VERSION "1.2"

NS_ :

BS_:
BU_: AMK_Inverter

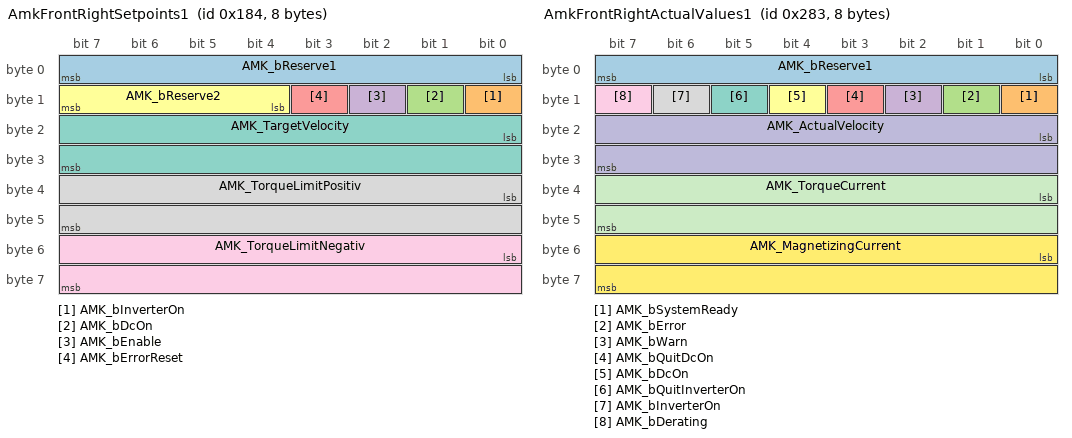
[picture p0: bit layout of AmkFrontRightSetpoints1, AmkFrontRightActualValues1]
BO_ 388 AmkFrontRightSetpoints1: 8 AMK_Inverter
 SG_ AMK_bReserve1           : 0|8@1+ (1,0) [0|255] "" Vector__XXX
 SG_ AMK_bInverterOn         : 8|1@1+ (1,0) [0|1]   "" Vector__XXX
 SG_ AMK_bDcOn               : 9|1@1+ (1,0) [0|1]   "" Vector__XXX
 SG_ AMK_bEnable             : 10|1@1+ (1,0) [0|1]  "" Vector__XXX
 SG_ AMK_bErrorReset         : 11|1@1+ (1,0) [0|1]  "" Vector__XXX
 SG_ AMK_bReserve2           : 12|4@1+ (1,0) [0|15]  "" Vector__XXX
 SG_ AMK_TargetVelocity      : 16|16@1- (1,0) [-32768|32767] "" Vector__XXX
 SG_ AMK_TorqueLimitPositiv  : 32|16@1- (1,0) [-32768|32767] "" Vector__XXX
 SG_ AMK_TorqueLimitNegativ  : 48|16@1- (1,0) [-32768|32767] "" Vector__XXX

BO_ 643 AmkFrontRightActualValues1: 8 AMK_Inverter
 SG_ AMK_bReserve1           : 0|8@1+ (1,0) [0|255] "" Vector__XXX
 SG_ AMK_bSystemReady        : 8|1@1+ (1,0) [0|1]   "" Vector__XXX
 SG_ AMK_bError              : 9|1@1+ (1,0) [0|1]   "" Vector__XXX
 SG_ AMK_bWarn               : 10|1@1+ (1,0) [0|1]  "" Vector__XXX
 SG_ AMK_bQuitDcOn           : 11|1@1+ (1,0) [0|1]  "" Vector__XXX
 SG_ AMK_bDcOn               : 12|1@1+ (1,0) [0|1]  "" Vector__XXX
 SG_ AMK_bQuitInverterOn     : 13|1@1+ (1,0) [0|1]  "" Vector__XXX
 SG_ AMK_bInverterOn         : 14|1@1+ (1,0) [0|1]  "" Vector__XXX
 SG_ AMK_bDerating           : 15|1@1+ (1,0) [0|1]  "" Vector__XXX
 SG_ AMK_ActualVelocity      : 16|16@1- (1,0) [-32768|32767] "" Vector__XXX
 SG_ AMK_TorqueCurrent       : 32|16@1- (1,0) [-32768|32767] "" Vector__XXX
 SG_ AMK_MagnetizingCurrent  : 48|16@1- (1,0) [-32768|32767] "" Vector__XXX

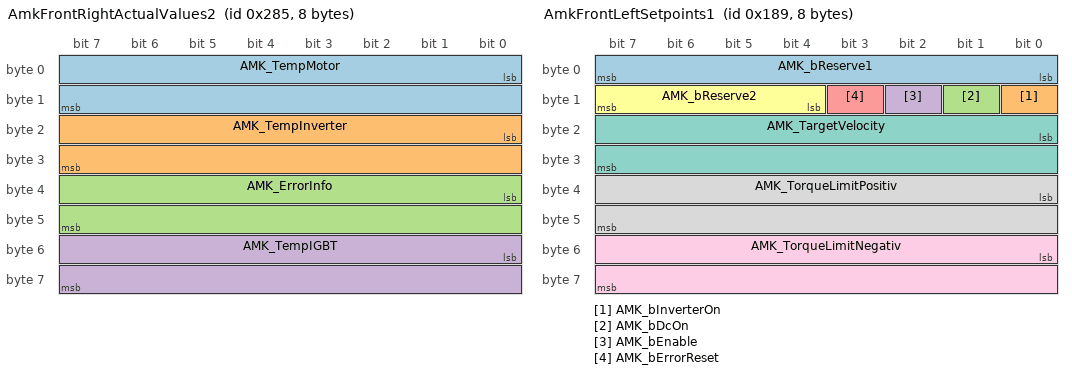
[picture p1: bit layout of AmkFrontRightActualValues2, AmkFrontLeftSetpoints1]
BO_ 645 AmkFrontRightActualValues2: 8 AMK_Inverter
 SG_ AMK_TempMotor           : 0|16@1- (1,0) [-32768|32767] "" Vector__XXX
 SG_ AMK_TempInverter        : 16|16@1- (1,0) [-32768|32767] "" Vector__XXX
 SG_ AMK_ErrorInfo           : 32|16@1+ (1,0) [0|65535]      "" Vector__XXX
 SG_ AMK_TempIGBT            : 48|16@1- (1,0) [-32768|32767] "" Vector__XXX

BO_ 393 AmkFrontLeftSetpoints1: 8 AMK_Inverter
 SG_ AMK_bReserve1           : 0|8@1+ (1,0) [0|255] "" Vector__XXX
 SG_ AMK_bInverterOn         : 8|1@1+ (1,0) [0|1]   "" Vector__XXX
 SG_ AMK_bDcOn               : 9|1@1+ (1,0) [0|1]   "" Vector__XXX
 SG_ AMK_bEnable             : 10|1@1+ (1,0) [0|1]  "" Vector__XXX
 SG_ AMK_bErrorReset         : 11|1@1+ (1,0) [0|1]  "" Vector__XXX
 SG_ AMK_bReserve2           : 12|4@1+ (1,0) [0|15]  "" Vector__XXX
 SG_ AMK_TargetVelocity      : 16|16@1- (1,0) [-32768|32767] "" Vector__XXX
 SG_ AMK_TorqueLimitPositiv  : 32|16@1- (1,0) [-32768|32767] "" Vector__XXX
 SG_ AMK_TorqueLimitNegativ  : 48|16@1- (1,0) [-32768|32767] "" Vector__XXX

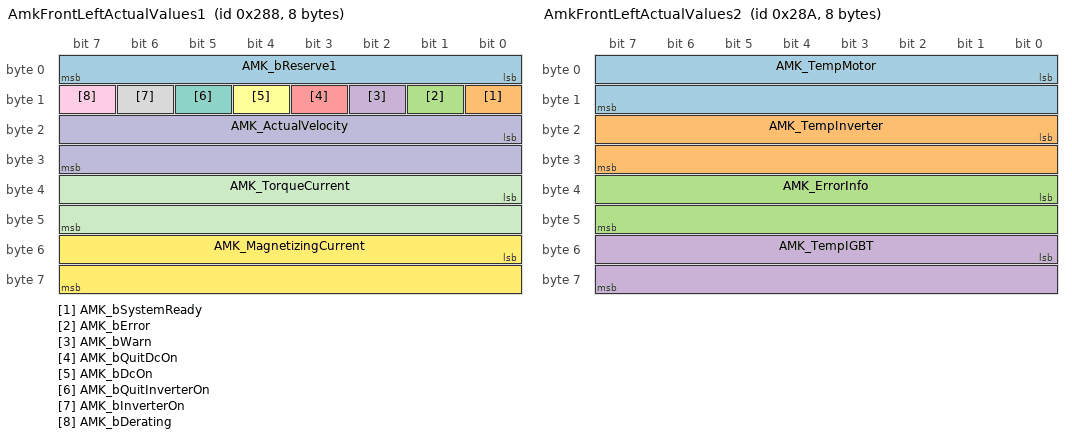
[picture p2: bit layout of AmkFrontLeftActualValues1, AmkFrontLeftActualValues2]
BO_ 648 AmkFrontLeftActualValues1: 8 AMK_Inverter
 SG_ AMK_bReserve1           : 0|8@1+ (1,0) [0|255] "" Vector__XXX
 SG_ AMK_bSystemReady        : 8|1@1+ (1,0) [0|1]   "" Vector__XXX
 SG_ AMK_bError              : 9|1@1+ (1,0) [0|1]   "" Vector__XXX
 SG_ AMK_bWarn               : 10|1@1+ (1,0) [0|1]  "" Vector__XXX
 SG_ AMK_bQuitDcOn           : 11|1@1+ (1,0) [0|1]  "" Vector__XXX
 SG_ AMK_bDcOn               : 12|1@1+ (1,0) [0|1]  "" Vector__XXX
 SG_ AMK_bQuitInverterOn     : 13|1@1+ (1,0) [0|1]  "" Vector__XXX
 SG_ AMK_bInverterOn         : 14|1@1+ (1,0) [0|1]  "" Vector__XXX
 SG_ AMK_bDerating           : 15|1@1+ (1,0) [0|1]  "" Vector__XXX
 SG_ AMK_ActualVelocity      : 16|16@1- (1,0) [-32768|32767] "" Vector__XXX
 SG_ AMK_TorqueCurrent       : 32|16@1- (1,0) [-32768|32767] "" Vector__XXX
 SG_ AMK_MagnetizingCurrent  : 48|16@1- (1,0) [-32768|32767] "" Vector__XXX

BO_ 650 AmkFrontLeftActualValues2: 8 AMK_Inverter
 SG_ AMK_TempMotor           : 0|16@1- (1,0) [-32768|32767] "" Vector__XXX
 SG_ AMK_TempInverter        : 16|16@1- (1,0) [-32768|32767] "" Vector__XXX
 SG_ AMK_ErrorInfo           : 32|16@1+ (1,0) [0|65535]      "" Vector__XXX
 SG_ AMK_TempIGBT            : 48|16@1- (1,0) [-32768|32767] "" Vector__XXX

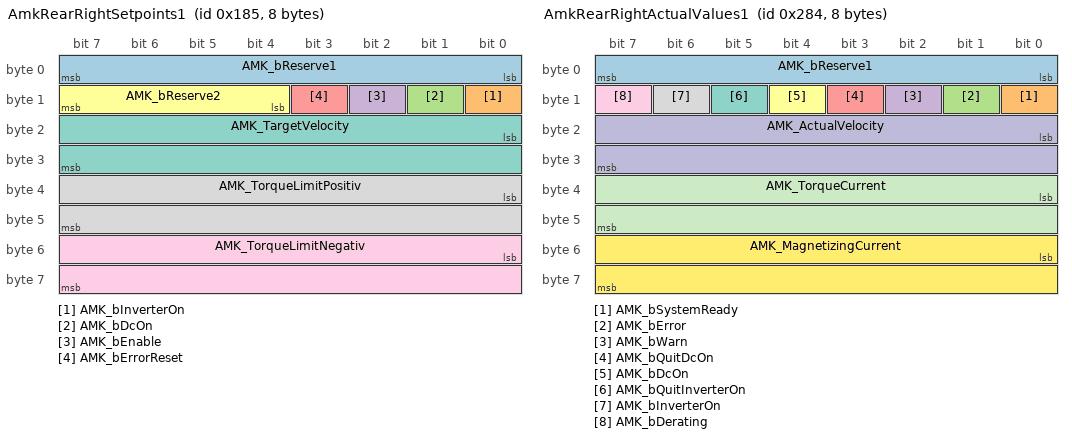
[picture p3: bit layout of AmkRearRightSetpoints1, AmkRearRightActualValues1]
BO_ 389 AmkRearRightSetpoints1: 8 AMK_Inverter
 SG_ AMK_bReserve1           : 0|8@1+ (1,0) [0|255] "" Vector__XXX
 SG_ AMK_bInverterOn         : 8|1@1+ (1,0) [0|1]   "" Vector__XXX
 SG_ AMK_bDcOn               : 9|1@1+ (1,0) [0|1]   "" Vector__XXX
 SG_ AMK_bEnable             : 10|1@1+ (1,0) [0|1]  "" Vector__XXX
 SG_ AMK_bErrorReset         : 11|1@1+ (1,0) [0|1]  "" Vector__XXX
 SG_ AMK_bReserve2           : 12|4@1+ (1,0) [0|15]  "" Vector__XXX
 SG_ AMK_TargetVelocity      : 16|16@1- (1,0) [-32768|32767] "" Vector__XXX
 SG_ AMK_TorqueLimitPositiv  : 32|16@1- (1,0) [-32768|32767] "" Vector__XXX
 SG_ AMK_TorqueLimitNegativ  : 48|16@1- (1,0) [-32768|32767] "" Vector__XXX

BO_ 644 AmkRearRightActualValues1: 8 AMK_Inverter
 SG_ AMK_bReserve1           : 0|8@1+ (1,0) [0|255] "" Vector__XXX
 SG_ AMK_bSystemReady        : 8|1@1+ (1,0) [0|1]   "" Vector__XXX
 SG_ AMK_bError              : 9|1@1+ (1,0) [0|1]   "" Vector__XXX
 SG_ AMK_bWarn               : 10|1@1+ (1,0) [0|1]  "" Vector__XXX
 SG_ AMK_bQuitDcOn           : 11|1@1+ (1,0) [0|1]  "" Vector__XXX
 SG_ AMK_bDcOn               : 12|1@1+ (1,0) [0|1]  "" Vector__XXX
 SG_ AMK_bQuitInverterOn     : 13|1@1+ (1,0) [0|1]  "" Vector__XXX
 SG_ AMK_bInverterOn         : 14|1@1+ (1,0) [0|1]  "" Vector__XXX
 SG_ AMK_bDerating           : 15|1@1+ (1,0) [0|1]  "" Vector__XXX
 SG_ AMK_ActualVelocity      : 16|16@1- (1,0) [-32768|32767] "" Vector__XXX
 SG_ AMK_TorqueCurrent       : 32|16@1- (1,0) [-32768|32767] "" Vector__XXX
 SG_ AMK_MagnetizingCurrent  : 48|16@1- (1,0) [-32768|32767] "" Vector__XXX

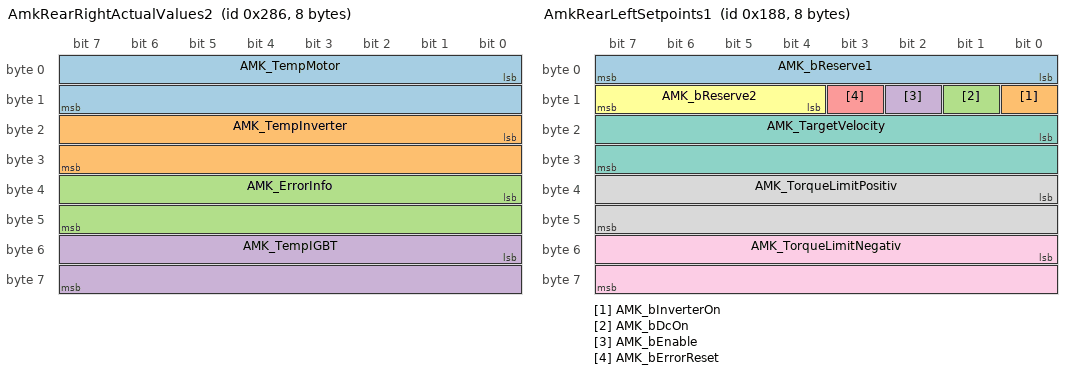
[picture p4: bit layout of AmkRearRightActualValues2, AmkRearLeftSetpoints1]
BO_ 646 AmkRearRightActualValues2: 8 AMK_Inverter
 SG_ AMK_TempMotor           : 0|16@1- (1,0) [-32768|32767] "" Vector__XXX
 SG_ AMK_TempInverter        : 16|16@1- (1,0) [-32768|32767] "" Vector__XXX
 SG_ AMK_ErrorInfo           : 32|16@1+ (1,0) [0|65535]      "" Vector__XXX
 SG_ AMK_TempIGBT            : 48|16@1- (1,0) [-32768|32767] "" Vector__XXX

BO_ 392 AmkRearLeftSetpoints1: 8 AMK_Inverter
 SG_ AMK_bReserve1           : 0|8@1+ (1,0) [0|255] "" Vector__XXX
 SG_ AMK_bInverterOn         : 8|1@1+ (1,0) [0|1]   "" Vector__XXX
 SG_ AMK_bDcOn               : 9|1@1+ (1,0) [0|1]   "" Vector__XXX
 SG_ AMK_bEnable             : 10|1@1+ (1,0) [0|1]  "" Vector__XXX
 SG_ AMK_bErrorReset         : 11|1@1+ (1,0) [0|1]  "" Vector__XXX
 SG_ AMK_bReserve2           : 12|4@1+ (1,0) [0|15]  "" Vector__XXX
 SG_ AMK_TargetVelocity      : 16|16@1- (1,0) [-32768|32767] "" Vector__XXX
 SG_ AMK_TorqueLimitPositiv  : 32|16@1- (1,0) [-32768|32767] "" Vector__XXX
 SG_ AMK_TorqueLimitNegativ  : 48|16@1- (1,0) [-32768|32767] "" Vector__XXX

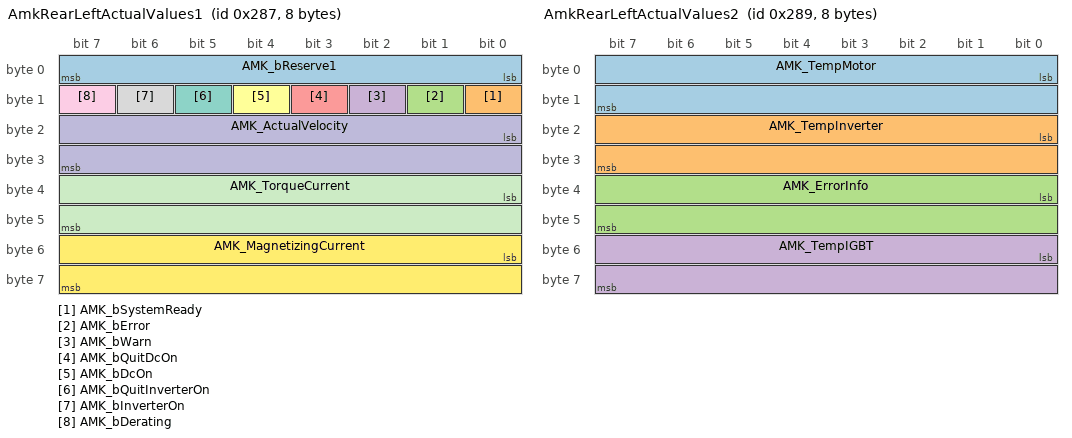
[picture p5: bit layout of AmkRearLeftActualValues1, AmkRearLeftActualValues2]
BO_ 647 AmkRearLeftActualValues1: 8 AMK_Inverter
 SG_ AMK_bReserve1           : 0|8@1+ (1,0) [0|255] "" Vector__XXX
 SG_ AMK_bSystemReady        : 8|1@1+ (1,0) [0|1]   "" Vector__XXX
 SG_ AMK_bError              : 9|1@1+ (1,0) [0|1]   "" Vector__XXX
 SG_ AMK_bWarn               : 10|1@1+ (1,0) [0|1]  "" Vector__XXX
 SG_ AMK_bQuitDcOn           : 11|1@1+ (1,0) [0|1]  "" Vector__XXX
 SG_ AMK_bDcOn               : 12|1@1+ (1,0) [0|1]  "" Vector__XXX
 SG_ AMK_bQuitInverterOn     : 13|1@1+ (1,0) [0|1]  "" Vector__XXX
 SG_ AMK_bInverterOn         : 14|1@1+ (1,0) [0|1]  "" Vector__XXX
 SG_ AMK_bDerating           : 15|1@1+ (1,0) [0|1]  "" Vector__XXX
 SG_ AMK_ActualVelocity      : 16|16@1- (1,0) [-32768|32767] "" Vector__XXX
 SG_ AMK_TorqueCurrent       : 32|16@1- (1,0) [-32768|32767] "" Vector__XXX
 SG_ AMK_MagnetizingCurrent  : 48|16@1- (1,0) [-32768|32767] "" Vector__XXX

BO_ 649 AmkRearLeftActualValues2: 8 AMK_Inverter
 SG_ AMK_TempMotor           : 0|16@1- (1,0) [-32768|32767] "" Vector__XXX
 SG_ AMK_TempInverter        : 16|16@1- (1,0) [-32768|32767] "" Vector__XXX
 SG_ AMK_ErrorInfo           : 32|16@1+ (1,0) [0|65535]      "" Vector__XXX
 SG_ AMK_TempIGBT            : 48|16@1- (1,0) [-32768|32767] "" Vector__XXX
